AUTOSAR XML (schema 4-2-2)
package /Components
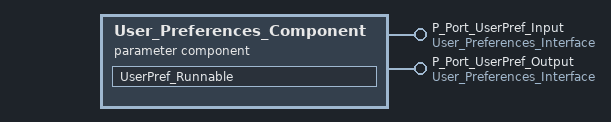
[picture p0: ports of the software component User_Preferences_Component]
  parameter sw component type User_Preferences_Component
    provide port P_Port_UserPref_Input: provided-interface=User_Preferences_Interface
    provide port P_Port_UserPref_Output: provided-interface=User_Preferences_Interface
    behavior User_Preferences_Behavior: handle-termination-and-restart=true
      init event Init_E: start-on-event=UserPref_Runnable
      runnable UserPref_Runnable: minimum-start-interval=100, can-be-invoked-concurrently=true, symbol=UserPref_Runnable_Symbol
        data-read-access:
          access Read_BR_Preset: accessed-variable=ENVIRONMENT_DATA
        data-send-points:
          access Send_Brightness_Preset: accessed-variable=ENVIRONMENT_DATA
